VERSION ""

NS_ :

BS_:
BU_: HV_BATTERY_MODULES CONTACTOR_CONTROLLER
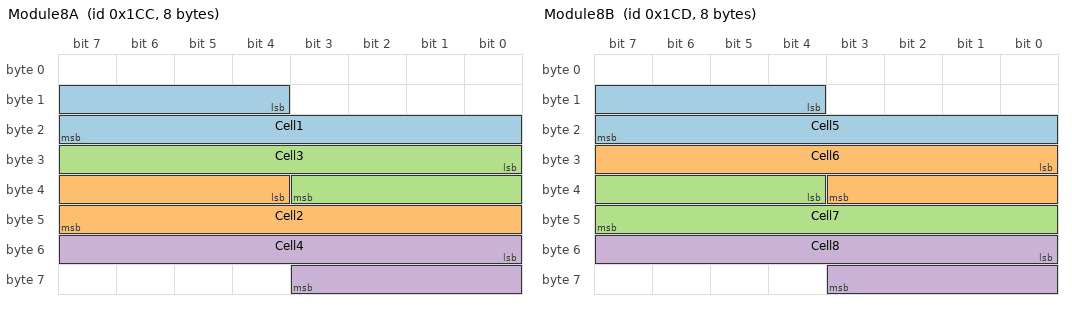
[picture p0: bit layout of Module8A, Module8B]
BO_ 460 Module8A: 8 HV_BATTERY_MODULES
   SG_ Cell1 : 12|12@1+ (1,1000) [0|0] "mV" Vector__XXX
   SG_ Cell2 : 36|12@1+ (1,1000) [0|0] "mV" Vector__XXX
   SG_ Cell3 : 24|12@1+ (1,1000) [0|0] "mV" Vector__XXX
   SG_ Cell4 : 48|12@1+ (1,1000) [0|0] "mV" Vector__XXX

BO_ 461 Module8B: 8 HV_BATTERY_MODULES
   SG_ Cell5 : 12|12@1+ (1,1000) [0|0] "mV" Vector__XXX
   SG_ Cell6 : 24|12@1+ (1,1000) [0|0] "mV" Vector__XXX
   SG_ Cell7 : 36|12@1+ (1,1000) [0|0] "mV" Vector__XXX
   SG_ Cell8 : 48|12@1+ (1,1000) [0|0] "mV" Vector__XXX

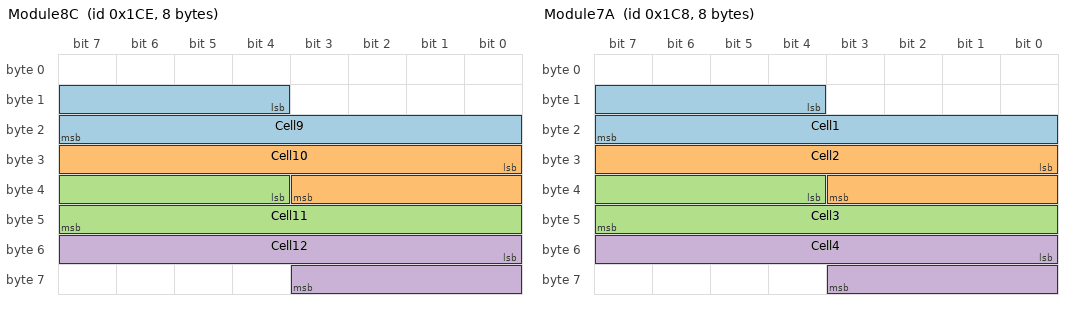
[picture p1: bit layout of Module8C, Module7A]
BO_ 462 Module8C: 8 HV_BATTERY_MODULES
   SG_ Cell9 : 12|12@1+ (1,1000) [0|0] "mV" Vector__XXX
   SG_ Cell10 : 24|12@1+ (1,1000) [0|0] "mV" Vector__XXX
   SG_ Cell11 : 36|12@1+ (1,1000) [0|0] "mV" Vector__XXX
   SG_ Cell12 : 48|12@1+ (1,1000) [0|0] "mV" Vector__XXX

BO_ 456 Module7A: 8 HV_BATTERY_MODULES
   SG_ Cell1 : 12|12@1+ (1,1000) [0|0] "mV" Vector__XXX
   SG_ Cell2 : 24|12@1+ (1,1000) [0|0] "mV" Vector__XXX
   SG_ Cell3 : 36|12@1+ (1,1000) [0|0] "mV" Vector__XXX
   SG_ Cell4 : 48|12@1+ (1,1000) [0|0] "mV" Vector__XXX

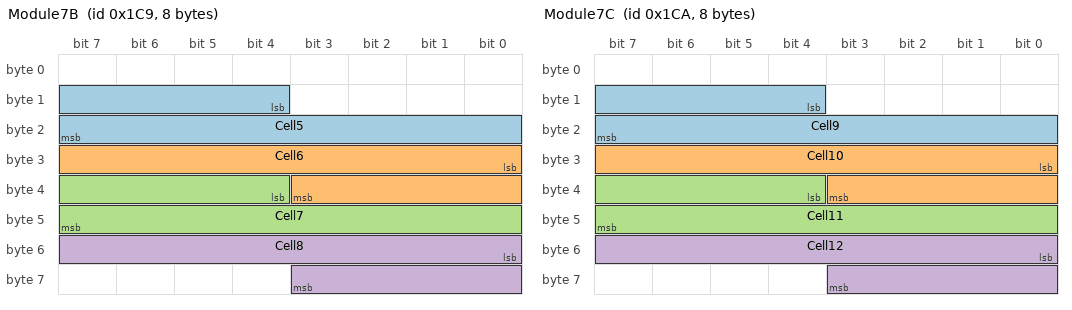
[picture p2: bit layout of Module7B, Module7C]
BO_ 457 Module7B: 8 HV_BATTERY_MODULES
   SG_ Cell5 : 12|12@1+ (1,1000) [0|0] "mV" Vector__XXX
   SG_ Cell6 : 24|12@1+ (1,1000) [0|0] "mV" Vector__XXX
   SG_ Cell7 : 36|12@1+ (1,1000) [0|0] "mV" Vector__XXX
   SG_ Cell8 : 48|12@1+ (1,1000) [0|0] "mV" Vector__XXX

BO_ 458 Module7C: 8 HV_BATTERY_MODULES
   SG_ Cell9 : 12|12@1+ (1,1000) [0|0] "mV" Vector__XXX
   SG_ Cell10 : 24|12@1+ (1,1000) [0|0] "mV" Vector__XXX
   SG_ Cell11 : 36|12@1+ (1,1000) [0|0] "mV" Vector__XXX
   SG_ Cell12 : 48|12@1+ (1,1000) [0|0] "mV" Vector__XXX

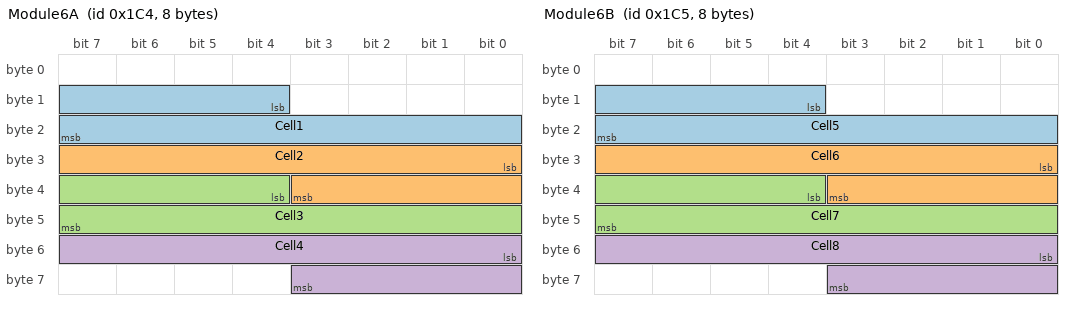
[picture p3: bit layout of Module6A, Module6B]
BO_ 452 Module6A: 8 HV_BATTERY_MODULES
   SG_ Cell1 : 12|12@1+ (1,1000) [0|0] "mV" Vector__XXX
   SG_ Cell2 : 24|12@1+ (1,1000) [0|0] "mV" Vector__XXX
   SG_ Cell3 : 36|12@1+ (1,1000) [0|0] "mV" Vector__XXX
   SG_ Cell4 : 48|12@1+ (1,1000) [0|0] "mV" Vector__XXX

BO_ 453 Module6B: 8 HV_BATTERY_MODULES
   SG_ Cell5 : 12|12@1+ (1,1000) [0|0] "mV" Vector__XXX
   SG_ Cell6 : 24|12@1+ (1,1000) [0|0] "mV" Vector__XXX
   SG_ Cell7 : 36|12@1+ (1,1000) [0|0] "mV" Vector__XXX
   SG_ Cell8 : 48|12@1+ (1,1000) [0|0] "mV" Vector__XXX

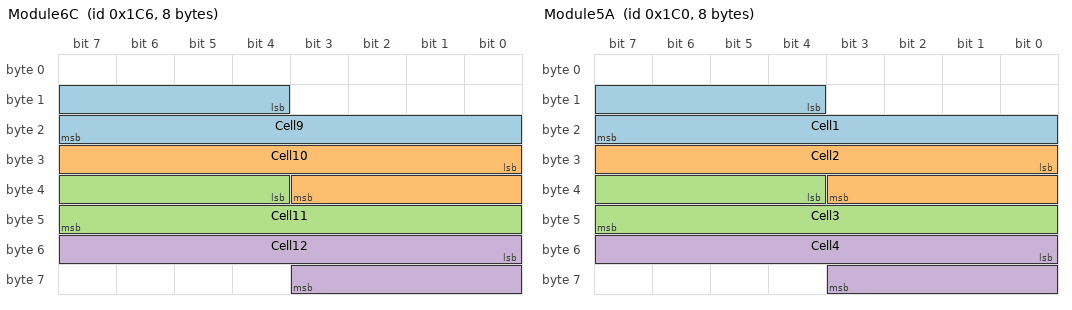
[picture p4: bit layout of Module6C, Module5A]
BO_ 454 Module6C: 8 HV_BATTERY_MODULES
   SG_ Cell9 : 12|12@1+ (1,1000) [0|0] "mV" Vector__XXX
   SG_ Cell10 : 24|12@1+ (1,1000) [0|0] "mV" Vector__XXX
   SG_ Cell11 : 36|12@1+ (1,1000) [0|0] "mV" Vector__XXX
   SG_ Cell12 : 48|12@1+ (1,1000) [0|0] "mV" Vector__XXX

BO_ 448 Module5A: 8 HV_BATTERY_MODULES
   SG_ Cell1 : 12|12@1+ (1,1000) [0|0] "mV" Vector__XXX
   SG_ Cell2 : 24|12@1+ (1,1000) [0|0] "mV" Vector__XXX
   SG_ Cell3 : 36|12@1+ (1,1000) [0|0] "mV" Vector__XXX
   SG_ Cell4 : 48|12@1+ (1,1000) [0|0] "mV" Vector__XXX

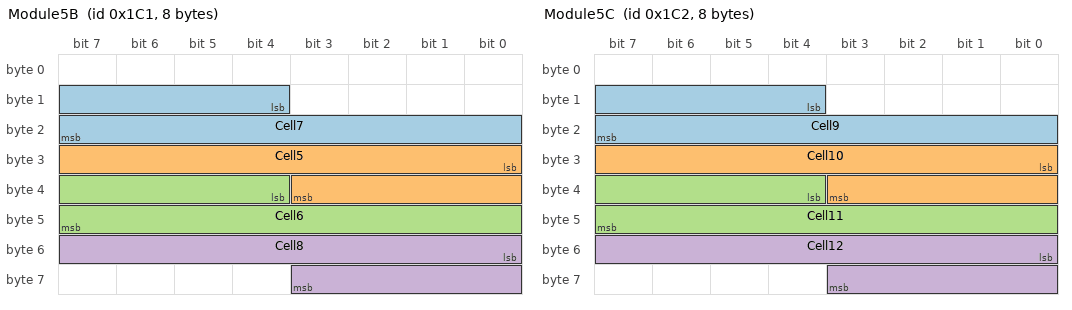
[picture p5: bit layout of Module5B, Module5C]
BO_ 449 Module5B: 8 HV_BATTERY_MODULES
   SG_ Cell7 : 12|12@1+ (1,1000) [0|0] "mV" Vector__XXX
   SG_ Cell5 : 24|12@1+ (1,1000) [0|0] "mV" Vector__XXX
   SG_ Cell6 : 36|12@1+ (1,1000) [0|0] "mV" Vector__XXX
   SG_ Cell8 : 48|12@1+ (1,1000) [0|0] "mV" Vector__XXX

BO_ 450 Module5C: 8 HV_BATTERY_MODULES
   SG_ Cell9 : 12|12@1+ (1,1000) [0|0] "mV" Vector__XXX
   SG_ Cell10 : 24|12@1+ (1,1000) [0|0] "mV" Vector__XXX
   SG_ Cell11 : 36|12@1+ (1,1000) [0|0] "mV" Vector__XXX
   SG_ Cell12 : 48|12@1+ (1,1000) [0|0] "mV" Vector__XXX

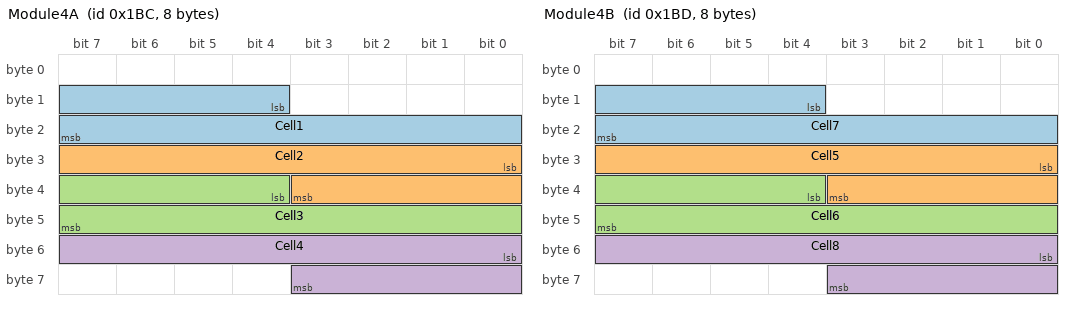
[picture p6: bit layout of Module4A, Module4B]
BO_ 444 Module4A: 8 HV_BATTERY_MODULES
   SG_ Cell1 : 12|12@1+ (1,1000) [0|0] "mV" Vector__XXX
   SG_ Cell2 : 24|12@1+ (1,1000) [0|0] "mV" Vector__XXX
   SG_ Cell3 : 36|12@1+ (1,1000) [0|0] "mV" Vector__XXX
   SG_ Cell4 : 48|12@1+ (1,1000) [0|0] "mV" Vector__XXX

BO_ 445 Module4B: 8 HV_BATTERY_MODULES
   SG_ Cell7 : 12|12@1+ (1,1000) [0|0] "mV" Vector__XXX
   SG_ Cell5 : 24|12@1+ (1,1000) [0|0] "mV" Vector__XXX
   SG_ Cell6 : 36|12@1+ (1,1000) [0|0] "mV" Vector__XXX
   SG_ Cell8 : 48|12@1+ (1,1000) [0|0] "mV" Vector__XXX

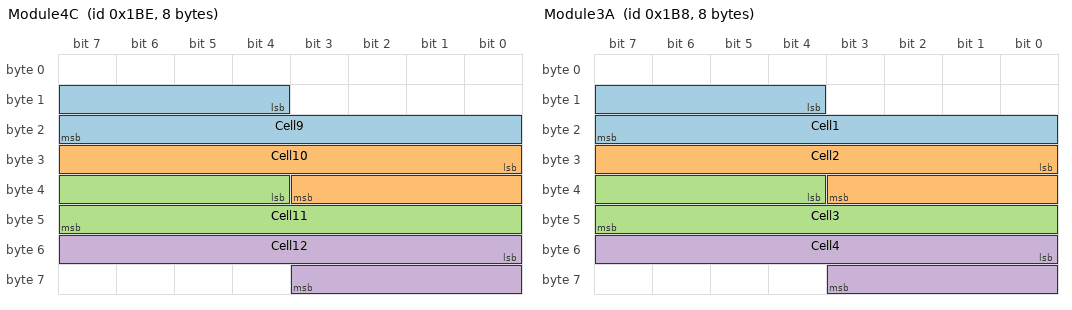
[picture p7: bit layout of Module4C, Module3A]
BO_ 446 Module4C: 8 HV_BATTERY_MODULES
   SG_ Cell9 : 12|12@1+ (1,1000) [0|0] "mV" Vector__XXX
   SG_ Cell10 : 24|12@1+ (1,1000) [0|0] "mV" Vector__XXX
   SG_ Cell11 : 36|12@1+ (1,1000) [0|0] "mV" Vector__XXX
   SG_ Cell12 : 48|12@1+ (1,1000) [0|0] "mV" Vector__XXX

BO_ 440 Module3A: 8 HV_BATTERY_MODULES
   SG_ Cell1 : 12|12@1+ (1,1000) [0|0] "mV" Vector__XXX
   SG_ Cell2 : 24|12@1+ (1,1000) [0|0] "mV" Vector__XXX
   SG_ Cell3 : 36|12@1+ (1,1000) [0|0] "mV" Vector__XXX
   SG_ Cell4 : 48|12@1+ (1,1000) [0|0] "mV" Vector__XXX

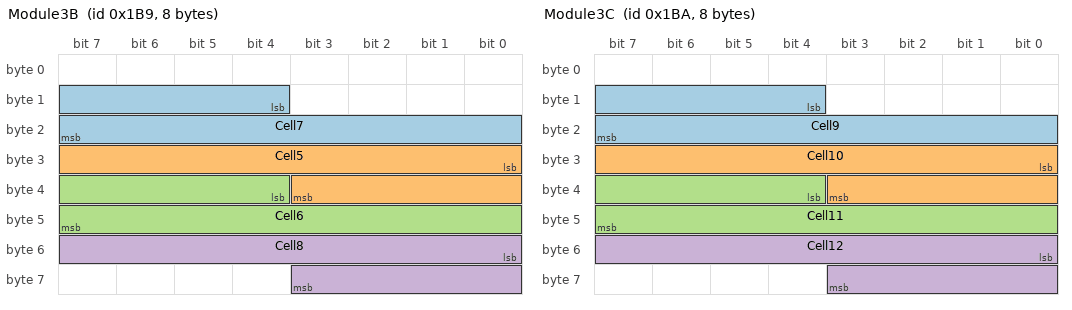
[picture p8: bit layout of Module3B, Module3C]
BO_ 441 Module3B: 8 HV_BATTERY_MODULES
   SG_ Cell7 : 12|12@1+ (1,1000) [0|0] "mV" Vector__XXX
   SG_ Cell5 : 24|12@1+ (1,1000) [0|0] "mV" Vector__XXX
   SG_ Cell6 : 36|12@1+ (1,1000) [0|0] "mV" Vector__XXX
   SG_ Cell8 : 48|12@1+ (1,1000) [0|0] "mV" Vector__XXX

BO_ 442 Module3C: 8 HV_BATTERY_MODULES
   SG_ Cell9 : 12|12@1+ (1,1000) [0|0] "mV" Vector__XXX
   SG_ Cell10 : 24|12@1+ (1,1000) [0|0] "mV" Vector__XXX
   SG_ Cell11 : 36|12@1+ (1,1000) [0|0] "mV" Vector__XXX
   SG_ Cell12 : 48|12@1+ (1,1000) [0|0] "mV" Vector__XXX

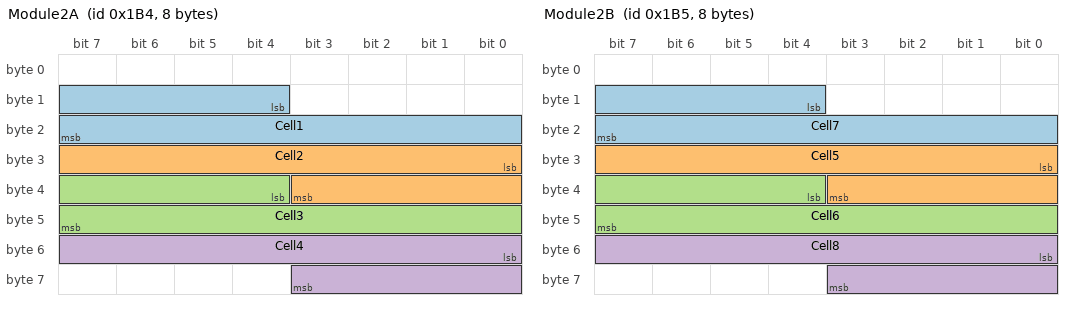
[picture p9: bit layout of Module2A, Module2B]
BO_ 436 Module2A: 8 HV_BATTERY_MODULES
   SG_ Cell1 : 12|12@1+ (1,1000) [0|0] "mV" Vector__XXX
   SG_ Cell2 : 24|12@1+ (1,1000) [0|0] "mV" Vector__XXX
   SG_ Cell3 : 36|12@1+ (1,1000) [0|0] "mV" Vector__XXX
   SG_ Cell4 : 48|12@1+ (1,1000) [0|0] "mV" Vector__XXX

BO_ 437 Module2B: 8 HV_BATTERY_MODULES
   SG_ Cell7 : 12|12@1+ (1,1000) [0|0] "mV" Vector__XXX
   SG_ Cell5 : 24|12@1+ (1,1000) [0|0] "mV" Vector__XXX
   SG_ Cell6 : 36|12@1+ (1,1000) [0|0] "mV" Vector__XXX
   SG_ Cell8 : 48|12@1+ (1,1000) [0|0] "mV" Vector__XXX

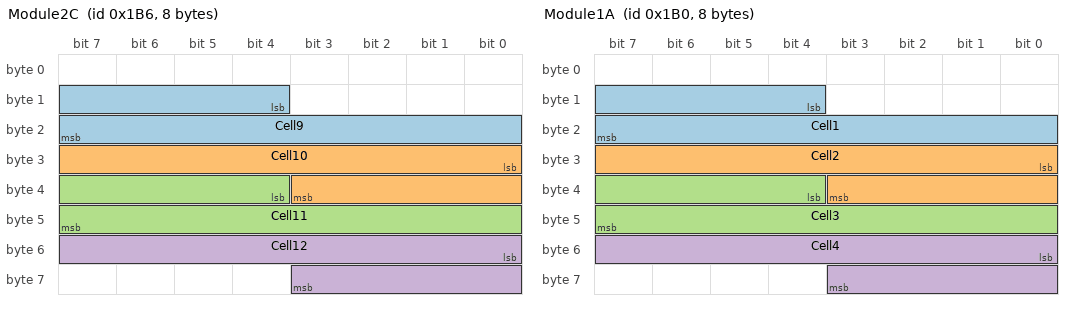
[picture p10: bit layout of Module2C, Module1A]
BO_ 438 Module2C: 8 HV_BATTERY_MODULES
   SG_ Cell9 : 12|12@1+ (1,1000) [0|0] "mV" Vector__XXX
   SG_ Cell10 : 24|12@1+ (1,1000) [0|0] "mV" Vector__XXX
   SG_ Cell11 : 36|12@1+ (1,1000) [0|0] "mV" Vector__XXX
   SG_ Cell12 : 48|12@1+ (1,1000) [0|0] "mV" Vector__XXX

BO_ 432 Module1A: 8 HV_BATTERY_MODULES
   SG_ Cell1 : 12|12@1+ (1,1000) [0|0] "mV" Vector__XXX
   SG_ Cell2 : 24|12@1+ (1,1000) [0|0] "mV" Vector__XXX
   SG_ Cell3 : 36|12@1+ (1,1000) [0|0] "mV" Vector__XXX
   SG_ Cell4 : 48|12@1+ (1,1000) [0|0] "mV" Vector__XXX

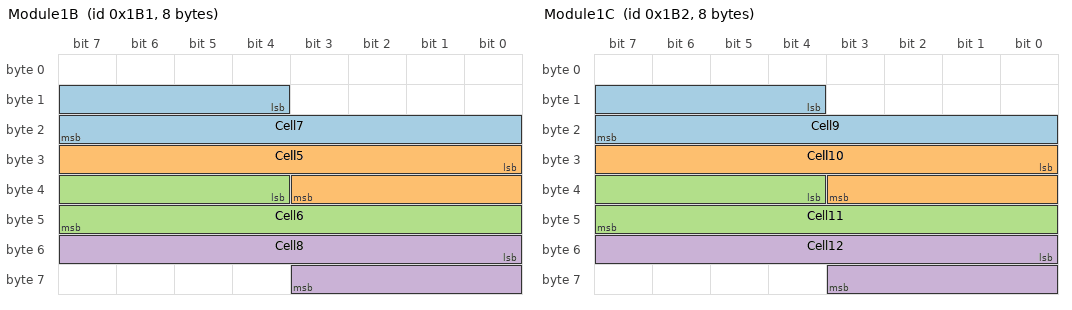
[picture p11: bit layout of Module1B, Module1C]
BO_ 433 Module1B: 8 HV_BATTERY_MODULES
   SG_ Cell7 : 12|12@1+ (1,1000) [0|0] "mV" Vector__XXX
   SG_ Cell5 : 24|12@1+ (1,1000) [0|0] "mV" Vector__XXX
   SG_ Cell6 : 36|12@1+ (1,1000) [0|0] "mV" Vector__XXX
   SG_ Cell8 : 48|12@1+ (1,1000) [0|0] "mV" Vector__XXX

BO_ 434 Module1C: 8 HV_BATTERY_MODULES
   SG_ Cell9 : 12|12@1+ (1,1000) [0|0] "mV" Vector__XXX
   SG_ Cell10 : 24|12@1+ (1,1000) [0|0] "mV" Vector__XXX
   SG_ Cell11 : 36|12@1+ (1,1000) [0|0] "mV" Vector__XXX
   SG_ Cell12 : 48|12@1+ (1,1000) [0|0] "mV" Vector__XXX

BO_ 187 Current_Shunt: 8 CONTACTOR_CONTROLLER
   SG_ Current : 8|16@1- (0.0025,0) [-200|200] "" CONTACTOR_CONTROLLER

BA_DEF_ BO_ "GenMsgBackgroundColor" STRING ;
BA_DEF_ BO_ "GenMsgForegroundColor" STRING ;
BA_DEF_DEF_ "GenMsgBackgroundColor" "#ffffff";
BA_DEF_DEF_ "GenMsgForegroundColor" "#000000";
